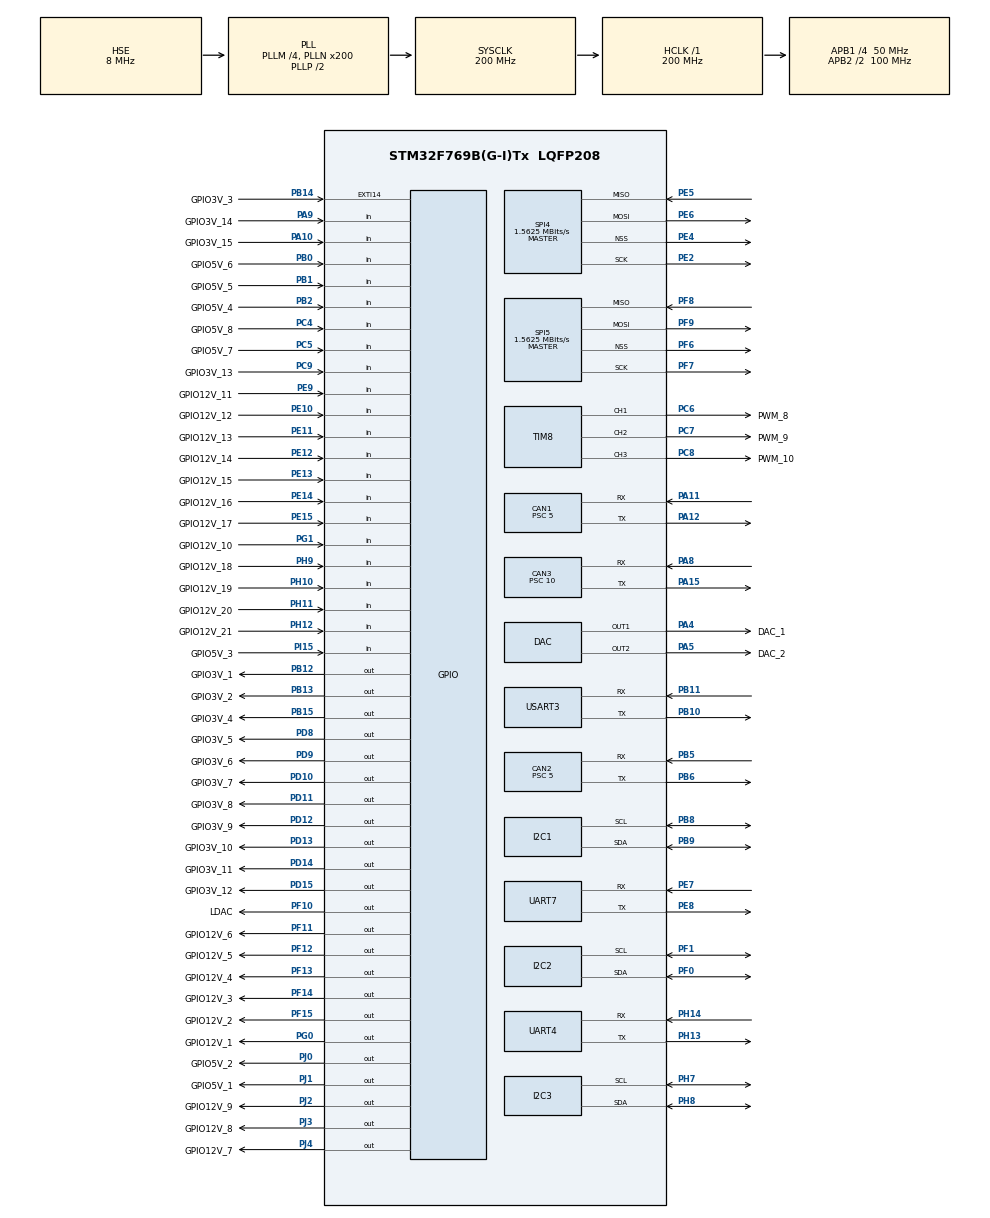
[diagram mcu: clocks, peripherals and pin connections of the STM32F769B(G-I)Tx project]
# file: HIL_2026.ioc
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CAN1.ABOM=ENABLE
CAN1.AWUM=ENABLE
CAN1.BS1=CAN_BS1_13TQ
CAN1.BS2=CAN_BS2_6TQ
CAN1.CalculateBaudRate=500000
CAN1.CalculateTimeBit=2000
CAN1.CalculateTimeQuantum=100.0
CAN1.NART=ENABLE
CAN1.Prescaler=5
CAN1.SJW=CAN_SJW_4TQ
CAN2.ABOM=ENABLE
CAN2.AWUM=ENABLE
CAN2.BS1=CAN_BS1_13TQ
CAN2.BS2=CAN_BS2_6TQ
CAN2.CalculateBaudRate=500000
CAN2.CalculateTimeBit=2000
CAN2.CalculateTimeQuantum=100.0
CAN2.NART=ENABLE
CAN2.Prescaler=5
CAN2.SJW=CAN_SJW_4TQ
CAN3.ABOM=DISABLE
CAN3.AWUM=DISABLE
CAN3.BS1=CAN_BS1_8TQ
CAN3.CalculateBaudRate=500000
CAN3.CalculateTimeBit=2000
CAN3.CalculateTimeQuantum=200.0
CAN3.NART=DISABLE
CAN3.Prescaler=10
CAN3.SJW=CAN_SJW_1TQ
CORTEX_M7.default_mode_Activation=1
Dma.Request0=UART4_RX
Dma.Request1=UART4_TX
Dma.UART4_RX.0.Direction=DMA_PERIPH_TO_MEMORY
Dma.UART4_RX.0.FIFOMode=DMA_FIFOMODE_DISABLE
Dma.UART4_RX.0.Instance=DMA1_Stream2
Dma.UART4_RX.0.MemDataAlignment=DMA_MDATAALIGN_BYTE
Dma.UART4_RX.0.MemInc=DMA_MINC_ENABLE
Dma.UART4_RX.0.Mode=DMA_CIRCULAR
Dma.UART4_RX.0.PeriphDataAlignment=DMA_PDATAALIGN_BYTE
Dma.UART4_RX.0.PeriphInc=DMA_PINC_DISABLE
Dma.UART4_RX.0.Priority=DMA_PRIORITY_LOW
Dma.UART4_TX.1.Direction=DMA_MEMORY_TO_PERIPH
Dma.UART4_TX.1.FIFOMode=DMA_FIFOMODE_DISABLE
Dma.UART4_TX.1.Instance=DMA1_Stream4
Dma.UART4_TX.1.MemDataAlignment=DMA_MDATAALIGN_BYTE
Dma.UART4_TX.1.MemInc=DMA_MINC_ENABLE
Dma.UART4_TX.1.Mode=DMA_NORMAL
Dma.UART4_TX.1.PeriphDataAlignment=DMA_PDATAALIGN_BYTE
Dma.UART4_TX.1.PeriphInc=DMA_PINC_DISABLE
Dma.UART4_TX.1.Priority=DMA_PRIORITY_LOW
FREERTOS.INCLUDE_uxTaskGetStackHighWaterMark=1
FREERTOS.INCLUDE_vTaskDelayUntil=1
FREERTOS.Tasks01=defaultTask,0,256,defaultTaskFunction,Default,NULL,Dynamic,NULL,NULL;printTaskName,-2,1000,printTask,As external,NULL,Dynamic,NULL,NULL;cliTaskName,-2,1000,cliTask,As external,NULL,Dynamic,NULL,NULL;mainTask,0,1000,mainTaskFunction,As external,NULL,Dynamic,NULL,NULL
FREERTOS.configCHECK_FOR_STACK_OVERFLOW=2
FREERTOS.configMINIMAL_STACK_SIZE=256
FREERTOS.configTOTAL_HEAP_SIZE=50000
I2C1.Timing=0x00C0EAFF
I2C2.Timing=0x00C0EAFF
I2C3.Timing=0x00C0EAFF
Mcu.Family=STM32F7
Mcu.Name=STM32F769B(G-I)Tx
Mcu.Package=LQFP208
NVIC.CAN3_RX0_IRQn=true\:5\:0\:true\:false\:true\:true\:true\:true\:true
NVIC.CAN3_RX1_IRQn=true\:5\:0\:true\:false\:true\:true\:true\:true\:true
NVIC.CAN3_SCE_IRQn=true\:5\:0\:true\:false\:true\:true\:true\:true\:true
NVIC.CAN3_TX_IRQn=true\:5\:0\:true\:false\:true\:true\:true\:true\:true
NVIC.DMA1_Stream2_IRQn=true\:5\:0\:false\:false\:true\:true\:false\:true\:true
NVIC.DMA1_Stream4_IRQn=true\:5\:0\:false\:false\:true\:true\:false\:true\:true
NVIC.PriorityGroup=NVIC_PRIORITYGROUP_4
NVIC.TIM1_UP_TIM10_IRQn=true\:15\:0\:false\:false\:true\:false\:false\:true\:true
NVIC.TimeBase=TIM1_UP_TIM10_IRQn
NVIC.TimeBaseIP=TIM1
PA10.GPIO_Label=GPIO3V_15
PA10.Signal=GPIO_Input
PA11.Mode=CAN_Activate
PA11.Signal=CAN1_RX
PA12.Mode=CAN_Activate
PA12.Signal=CAN1_TX
PA13.GPIO_Label=SWDIO
PA13.Mode=Serial_Wire
PA13.Signal=SYS_JTMS-SWDIO
PA14.GPIO_Label=SWCLK
PA14.Mode=Serial_Wire
PA14.Signal=SYS_JTCK-SWCLK
PA15.Mode=CAN_Activate
PA15.Signal=CAN3_TX
PA4.GPIO_Label=DAC_1
PA4.Signal=COMP_DAC1_group
PA5.GPIO_Label=DAC_2
PA5.Signal=COMP_DAC2_group
PA8.Mode=CAN_Activate
PA8.Signal=CAN3_RX
PA9.GPIO_Label=GPIO3V_14
PA9.Signal=GPIO_Input
PB0.GPIO_Label=GPIO5V_6
PB0.Signal=GPIO_Input
PB1.GPIO_Label=GPIO5V_5
PB1.Signal=GPIO_Input
PB10.Mode=Asynchronous
PB10.Signal=USART3_TX
PB11.GPIO_PuPd=GPIO_PULLUP
PB11.Mode=Asynchronous
PB11.Signal=USART3_RX
PB12.GPIO_Label=GPIO3V_1
PB12.Signal=GPIO_Output
PB13.GPIO_Label=GPIO3V_2
PB13.Signal=GPIO_Output
PB14.GPIO_Label=GPIO3V_3
PB14.Signal=GPXTI14
PB15.GPIO_Label=GPIO3V_4
PB15.Signal=GPIO_Output
PB2.GPIO_Label=GPIO5V_4
PB2.Signal=GPIO_Input
PB5.Mode=CAN_Activate
PB5.Signal=CAN2_RX
PB6.Mode=CAN_Activate
PB6.Signal=CAN2_TX
PB8.Mode=I2C
PB8.Signal=I2C1_SCL
PB9.Mode=I2C
PB9.Signal=I2C1_SDA
PC4.GPIO_Label=GPIO5V_8
PC4.Signal=GPIO_Input
PC5.GPIO_Label=GPIO5V_7
PC5.Signal=GPIO_Input
PC6.GPIO_Label=PWM_8
PC6.GPIO_Speed=GPIO_SPEED_FREQ_HIGH
PC6.Signal=S_TIM8_CH1
PC7.GPIO_Label=PWM_9
PC7.GPIO_Speed=GPIO_SPEED_FREQ_HIGH
PC7.Signal=S_TIM8_CH2
PC8.GPIO_Label=PWM_10
PC8.GPIO_Speed=GPIO_SPEED_FREQ_HIGH
PC8.Signal=S_TIM8_CH3
PC9.GPIO_Label=GPIO3V_13
PC9.Signal=GPIO_Input
PD10.GPIO_Label=GPIO3V_7
PD10.Signal=GPIO_Output
PD11.GPIO_Label=GPIO3V_8
PD11.Signal=GPIO_Output
PD12.GPIO_Label=GPIO3V_9
PD12.Signal=GPIO_Output
PD13.GPIO_Label=GPIO3V_10
PD13.Signal=GPIO_Output
PD14.GPIO_Label=GPIO3V_11
PD14.Signal=GPIO_Output
PD15.GPIO_Label=GPIO3V_12
PD15.Signal=GPIO_Output
PD8.GPIO_Label=GPIO3V_5
PD8.Signal=GPIO_Output
PD9.GPIO_Label=GPIO3V_6
PD9.Signal=GPIO_Output
PE10.GPIO_Label=GPIO12V_12
PE10.Signal=GPIO_Input
PE11.GPIO_Label=GPIO12V_13
PE11.Signal=GPIO_Input
PE12.GPIO_Label=GPIO12V_14
PE12.Signal=GPIO_Input
PE13.GPIO_Label=GPIO12V_15
PE13.Signal=GPIO_Input
PE14.GPIO_Label=GPIO12V_16
PE14.Signal=GPIO_Input
PE15.GPIO_Label=GPIO12V_17
PE15.Signal=GPIO_Input
PE2.Mode=Full_Duplex_Master
PE2.Signal=SPI4_SCK
PE4.Mode=NSS_Signal_Hard_Output
PE4.Signal=SPI4_NSS
PE5.Mode=Full_Duplex_Master
PE5.Signal=SPI4_MISO
PE6.Mode=Full_Duplex_Master
PE6.Signal=SPI4_MOSI
PE7.Mode=Asynchronous
PE7.Signal=UART7_RX
PE8.Mode=Asynchronous
PE8.Signal=UART7_TX
PE9.GPIO_Label=GPIO12V_11
PE9.Signal=GPIO_Input
PF0.Mode=I2C
PF0.Signal=I2C2_SDA
PF1.Mode=I2C
PF1.Signal=I2C2_SCL
PF10.GPIO_Label=LDAC
PF10.PinState=GPIO_PIN_SET
PF10.Signal=GPIO_Output
PF11.GPIO_Label=GPIO12V_6
PF11.Signal=GPIO_Output
PF12.GPIO_Label=GPIO12V_5
PF12.Signal=GPIO_Output
PF13.GPIO_Label=GPIO12V_4
PF13.Signal=GPIO_Output
PF14.GPIO_Label=GPIO12V_3
PF14.Signal=GPIO_Output
PF15.GPIO_Label=GPIO12V_2
PF15.Signal=GPIO_Output
PF6.Mode=NSS_Signal_Hard_Output
PF6.Signal=SPI5_NSS
PF7.Mode=Full_Duplex_Master
PF7.Signal=SPI5_SCK
PF8.Mode=Full_Duplex_Master
PF8.Signal=SPI5_MISO
PF9.Mode=Full_Duplex_Master
PF9.Signal=SPI5_MOSI
PG0.GPIO_Label=GPIO12V_1
PG0.Signal=GPIO_Output
PG1.GPIO_Label=GPIO12V_10
PG1.Signal=GPIO_Input
PH0/OSC_IN.GPIO_Label=OSC_OUT
PH0/OSC_IN.Mode=HSE-External-Oscillator
PH0/OSC_IN.Signal=RCC_OSC_IN
PH1/OSC_OUT.GPIO_Label=OSC_IN
PH1/OSC_OUT.Mode=HSE-External-Oscillator
PH1/OSC_OUT.Signal=RCC_OSC_OUT
PH10.GPIO_Label=GPIO12V_19
PH10.Signal=GPIO_Input
PH11.GPIO_Label=GPIO12V_20
PH11.Signal=GPIO_Input
PH12.GPIO_Label=GPIO12V_21
PH12.Signal=GPIO_Input
PH13.Mode=Asynchronous
PH13.Signal=UART4_TX
PH14.Mode=Asynchronous
PH14.Signal=UART4_RX
PH7.Mode=I2C
PH7.Signal=I2C3_SCL
PH8.Mode=I2C
PH8.Signal=I2C3_SDA
PH9.GPIO_Label=GPIO12V_18
PH9.Signal=GPIO_Input
PI15.GPIO_Label=GPIO5V_3
PI15.Signal=GPIO_Input
PJ0.GPIO_Label=GPIO5V_2
PJ0.Signal=GPIO_Output
PJ1.GPIO_Label=GPIO5V_1
PJ1.Signal=GPIO_Output
PJ2.GPIO_Label=GPIO12V_9
PJ2.Signal=GPIO_Output
PJ3.GPIO_Label=GPIO12V_8
PJ3.Signal=GPIO_Output
PJ4.GPIO_Label=GPIO12V_7
PJ4.Signal=GPIO_Output
ProjectManager.HeapSize=0x200
ProjectManager.StackSize=0x400
ProjectManager.TargetToolchain=Makefile
RCC.AHBFreq_Value=200000000
RCC.APB1CLKDivider=RCC_HCLK_DIV4
RCC.APB1Freq_Value=50000000
RCC.APB1TimFreq_Value=100000000
RCC.APB2CLKDivider=RCC_HCLK_DIV2
RCC.APB2Freq_Value=100000000
RCC.APB2TimFreq_Value=200000000
RCC.CortexFreq_Value=200000000
RCC.HCLKFreq_Value=200000000
RCC.HSE_VALUE=8000000
RCC.HSI_VALUE=16000000
RCC.LSE_VALUE=32768
RCC.PLLM=4
RCC.PLLN=200
RCC.PLLSourceVirtual=RCC_PLLSOURCE_HSE
RCC.SYSCLKFreq_VALUE=200000000
RCC.SYSCLKSource=RCC_SYSCLKSOURCE_PLLCLK
RCC.USBFreq_Value=200000000
RCC.VCOOutputFreq_Value=400000000
SH.COMP_DAC1_group.0=DAC_OUT1,DAC_OUT1
SH.COMP_DAC2_group.0=DAC_OUT2,DAC_OUT2
SH.S_TIM8_CH1.0=TIM8_CH1,PWM Generation1 CH1
SH.S_TIM8_CH2.0=TIM8_CH2,PWM Generation2 CH2
SH.S_TIM8_CH3.0=TIM8_CH3,PWM Generation3 CH3
SPI4.BaudRatePrescaler=SPI_BAUDRATEPRESCALER_64
SPI4.CalculateBaudRate=1.5625 MBits/s
SPI4.DataSize=SPI_DATASIZE_8BIT
SPI4.Direction=SPI_DIRECTION_2LINES
SPI4.Mode=SPI_MODE_MASTER
SPI4.VirtualNSS=VM_NSSHARD
SPI4.VirtualType=VM_MASTER
SPI5.BaudRatePrescaler=SPI_BAUDRATEPRESCALER_64
SPI5.CalculateBaudRate=1.5625 MBits/s
SPI5.DataSize=SPI_DATASIZE_8BIT
SPI5.Direction=SPI_DIRECTION_2LINES
SPI5.Mode=SPI_MODE_MASTER
SPI5.VirtualNSS=VM_NSSHARD
SPI5.VirtualType=VM_MASTER
TIM8.Channel-PWM\ Generation1\ CH1=TIM_CHANNEL_1
TIM8.Channel-PWM\ Generation2\ CH2=TIM_CHANNEL_2
TIM8.Channel-PWM\ Generation3\ CH3=TIM_CHANNEL_3
USART3.VirtualMode-Asynchronous=VM_ASYNC
VP_FREERTOS_VS_CMSIS_V1.Mode=CMSIS_V1
VP_SYS_VS_tim1.Mode=TIM1
VP_TIM7_VS_ClockSourceINT.Mode=Enable_Timer
board=custom

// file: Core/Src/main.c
/* USER CODE BEGIN Header */
/**
  ******************************************************************************
  * @file           : main.c
  * @brief          : Main program body
  ******************************************************************************
  * @attention
  *
  * Copyright (c) 2026 STMicroelectronics.
  * All rights reserved.
  *
  * This software is licensed under terms that can be found in the LICENSE file
  * in the root directory of this software component.
  * If no LICENSE file comes with this software, it is provided AS-IS.
  *
  ******************************************************************************
  */
/* USER CODE END Header */
#include "main.h"
#include "cmsis_os.h"
#include "can.h"
#include "dac.h"
#include "dma.h"
#include "i2c.h"
#include "spi.h"
#include "tim.h"
#include "usart.h"
#include "gpio.h"

void SystemClock_Config(void);
static void MPU_Config(void);
void MX_FREERTOS_Init(void);
/* USER CODE BEGIN PFP */
// Overridden by Src/userInit.c, which also creates HIL's FreeRTOS tasks
__weak void userInit() {}
/* USER CODE END PFP */

int main(void)
{

  /* MPU Configuration--------------------------------------------------------*/
  MPU_Config();

  /* MCU Configuration--------------------------------------------------------*/

  /* Reset of all peripherals, Initializes the Flash interface and the Systick. */
  HAL_Init();

  /* Configure the system clock */
  SystemClock_Config();

  /* Initialize all configured peripherals */
  MX_GPIO_Init();
  MX_DMA_Init();
  MX_CAN1_Init();
  MX_CAN2_Init();
  MX_CAN3_Init();
  MX_DAC_Init();
  MX_I2C1_Init();
  MX_I2C2_Init();
  MX_I2C3_Init();
  MX_SPI4_Init();
  MX_SPI5_Init();
  MX_TIM8_Init();
  MX_UART4_Init();
  MX_UART7_Init();
  MX_USART3_UART_Init();
  MX_TIM7_Init();
  /* USER CODE BEGIN 2 */
  userInit();
  /* USER CODE END 2 */

  /* Call init function for freertos objects (in cmsis_os2.c) */
  MX_FREERTOS_Init();

  /* Start scheduler */
  osKernelStart();

  /* We should never get here as control is now taken by the scheduler */

  /* Infinite loop */
  while (1)
  {

  }
}

void SystemClock_Config(void)
{
  RCC_OscInitTypeDef RCC_OscInitStruct = {0};
  RCC_ClkInitTypeDef RCC_ClkInitStruct = {0};

  /** Configure the main internal regulator output voltage
  */
  __HAL_RCC_PWR_CLK_ENABLE();
  __HAL_PWR_VOLTAGESCALING_CONFIG(PWR_REGULATOR_VOLTAGE_SCALE1);

  /** Initializes the RCC Oscillators according to the specified parameters
  * in the RCC_OscInitTypeDef structure.
  */
  RCC_OscInitStruct.OscillatorType = RCC_OSCILLATORTYPE_HSE;
  RCC_OscInitStruct.HSEState = RCC_HSE_ON;
  RCC_OscInitStruct.PLL.PLLState = RCC_PLL_ON;
  RCC_OscInitStruct.PLL.PLLSource = RCC_PLLSOURCE_HSE;
  RCC_OscInitStruct.PLL.PLLM = 4;
  RCC_OscInitStruct.PLL.PLLN = 200;
  RCC_OscInitStruct.PLL.PLLP = RCC_PLLP_DIV2;
  RCC_OscInitStruct.PLL.PLLQ = 2;
  RCC_OscInitStruct.PLL.PLLR = 2;
  if (HAL_RCC_OscConfig(&RCC_OscInitStruct) != HAL_OK)
  {
    Error_Handler();
  }

  /** Activate the Over-Drive mode
  */
  if (HAL_PWREx_EnableOverDrive() != HAL_OK)
  {
    Error_Handler();
  }

  /** Initializes the CPU, AHB and APB buses clocks
  */
  RCC_ClkInitStruct.ClockType = RCC_CLOCKTYPE_HCLK|RCC_CLOCKTYPE_SYSCLK
                              |RCC_CLOCKTYPE_PCLK1|RCC_CLOCKTYPE_PCLK2;
  RCC_ClkInitStruct.SYSCLKSource = RCC_SYSCLKSOURCE_PLLCLK;
  RCC_ClkInitStruct.AHBCLKDivider = RCC_SYSCLK_DIV1;
  RCC_ClkInitStruct.APB1CLKDivider = RCC_HCLK_DIV4;
  RCC_ClkInitStruct.APB2CLKDivider = RCC_HCLK_DIV2;

  if (HAL_RCC_ClockConfig(&RCC_ClkInitStruct, FLASH_LATENCY_6) != HAL_OK)
  {
    Error_Handler();
  }
}

 /* MPU Configuration */

void MPU_Config(void)
{
  MPU_Region_InitTypeDef MPU_InitStruct = {0};

  /* Disables the MPU */
  HAL_MPU_Disable();

  /** Initializes and configures the Region and the memory to be protected
  */
  MPU_InitStruct.Enable = MPU_REGION_ENABLE;
  MPU_InitStruct.Number = MPU_REGION_NUMBER0;
  MPU_InitStruct.BaseAddress = 0x0;
  MPU_InitStruct.Size = MPU_REGION_SIZE_4GB;
  MPU_InitStruct.SubRegionDisable = 0x87;
  MPU_InitStruct.TypeExtField = MPU_TEX_LEVEL0;
  MPU_InitStruct.AccessPermission = MPU_REGION_NO_ACCESS;
  MPU_InitStruct.DisableExec = MPU_INSTRUCTION_ACCESS_DISABLE;
  MPU_InitStruct.IsShareable = MPU_ACCESS_SHAREABLE;
  MPU_InitStruct.IsCacheable = MPU_ACCESS_NOT_CACHEABLE;
  MPU_InitStruct.IsBufferable = MPU_ACCESS_NOT_BUFFERABLE;

  HAL_MPU_ConfigRegion(&MPU_InitStruct);
  /* Enables the MPU */
  HAL_MPU_Enable(MPU_PRIVILEGED_DEFAULT);

}

void HAL_TIM_PeriodElapsedCallback(TIM_HandleTypeDef *htim)
{
  if (htim->Instance == TIM1)
  {
    HAL_IncTick();
  }
}

void Error_Handler(void)
{
  __disable_irq();
  while (1)
  {
  }
}

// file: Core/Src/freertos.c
/* USER CODE BEGIN Header */
/**
  ******************************************************************************
  * File Name          : freertos.c
  * Description        : Code for freertos applications
  ******************************************************************************
  * @attention
  *
  * Copyright (c) 2026 STMicroelectronics.
  * All rights reserved.
  *
  * This software is licensed under terms that can be found in the LICENSE file
  * in the root directory of this software component.
  * If no LICENSE file comes with this software, it is provided AS-IS.
  *
  ******************************************************************************
  */
/* USER CODE END Header */

#include "FreeRTOS.h"
#include "task.h"
#include "main.h"
#include "cmsis_os.h"

osThreadId defaultTaskHandle;
osThreadId printTaskNameHandle;
osThreadId cliTaskNameHandle;
osThreadId mainTaskHandle;

void defaultTaskFunction(void const * argument);
extern void printTask(void const * argument);
extern void cliTask(void const * argument);
extern void mainTaskFunction(void const * argument);

void MX_FREERTOS_Init(void); /* (MISRA C 2004 rule 8.1) */

/* GetIdleTaskMemory prototype (linked to static allocation support) */
void vApplicationGetIdleTaskMemory( StaticTask_t **ppxIdleTaskTCBBuffer, StackType_t **ppxIdleTaskStackBuffer, uint32_t *pulIdleTaskStackSize );

/* Hook prototypes */
void vApplicationStackOverflowHook(xTaskHandle xTask, signed char *pcTaskName);

/* USER CODE BEGIN 4 */
__weak void vApplicationStackOverflowHook(xTaskHandle xTask, signed char *pcTaskName)
{
   /* Run time stack overflow checking is performed if
   configCHECK_FOR_STACK_OVERFLOW is defined to 1 or 2. This hook function is
   called if a stack overflow is detected. */
}
/* USER CODE END 4 */

/* USER CODE BEGIN GET_IDLE_TASK_MEMORY */
static StaticTask_t xIdleTaskTCBBuffer;
static StackType_t xIdleStack[configMINIMAL_STACK_SIZE];

void vApplicationGetIdleTaskMemory( StaticTask_t **ppxIdleTaskTCBBuffer, StackType_t **ppxIdleTaskStackBuffer, uint32_t *pulIdleTaskStackSize )
{
  *ppxIdleTaskTCBBuffer = &xIdleTaskTCBBuffer;
  *ppxIdleTaskStackBuffer = &xIdleStack[0];
  *pulIdleTaskStackSize = configMINIMAL_STACK_SIZE;
  /* place for user code */
}
/* USER CODE END GET_IDLE_TASK_MEMORY */

void MX_FREERTOS_Init(void) {

  /* Create the thread(s) */
  /* definition and creation of defaultTask */
  osThreadDef(defaultTask, defaultTaskFunction, osPriorityNormal, 0, 256);
  defaultTaskHandle = osThreadCreate(osThread(defaultTask), NULL);

  /* definition and creation of printTaskName */
  osThreadDef(printTaskName, printTask, osPriorityLow, 0, 1000);
  printTaskNameHandle = osThreadCreate(osThread(printTaskName), NULL);

  /* definition and creation of cliTaskName */
  osThreadDef(cliTaskName, cliTask, osPriorityLow, 0, 1000);
  cliTaskNameHandle = osThreadCreate(osThread(cliTaskName), NULL);

  /* definition and creation of mainTask */
  osThreadDef(mainTask, mainTaskFunction, osPriorityNormal, 0, 1000);
  mainTaskHandle = osThreadCreate(osThread(mainTask), NULL);

}

void defaultTaskFunction(void const * argument)
{
  for(;;)
  {
    osDelay(1);
  }
}
